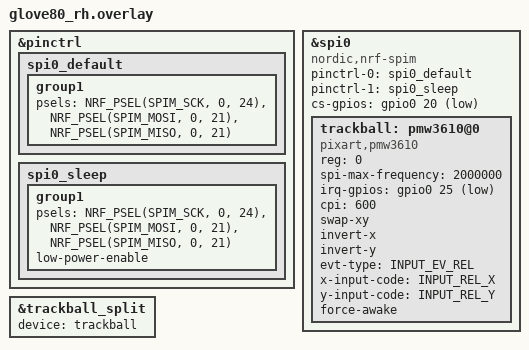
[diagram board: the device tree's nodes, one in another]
/*
 * Copyright (c) 2020 The ZMK Contributors
 *
 * SPDX-License-Identifier: MIT
 */

#include <zephyr/dt-bindings/input/input-event-codes.h>
#include "glove80.dtsi"

/* configure IO pins for the SPI */
&pinctrl {
    spi0_default: spi0_default {
        group1 {
            psels = <NRF_PSEL(SPIM_SCK, 0, 24)>,  // Adjust SCK pin
                    <NRF_PSEL(SPIM_MOSI, 0, 21)>, // Adjust MOSI pin
                    <NRF_PSEL(SPIM_MISO, 0, 21)>; // Adjust MISO pin
        };
    };

    spi0_sleep: spi0_sleep {
        group1 {
            psels = <NRF_PSEL(SPIM_SCK, 0, 24)>,
                    <NRF_PSEL(SPIM_MOSI, 0, 21)>,
                    <NRF_PSEL(SPIM_MISO, 0, 21)>;
            low-power-enable;
        };
    };
};


/* define and configure the trackball connected to SPI channel */
&spi0 {
    status = "okay";
    compatible = "nordic,nrf-spim";
    pinctrl-0 = <&spi0_default>;
    pinctrl-1 = <&spi0_sleep>;
    pinctrl-names = "default", "sleep";
    cs-gpios = <&gpio0 20 GPIO_ACTIVE_LOW>;  // Adjust CS pin

    trackball: pmw3610@0 {
        compatible = "pixart,pmw3610";
        reg = <0>;
        spi-max-frequency = <2000000>;
        irq-gpios = <&gpio0 25 (GPIO_ACTIVE_LOW | GPIO_PULL_UP)>;  // Adjust IRQ/Motion pin
        cpi = <600>;

        /* use the following defines below to properly *
        *  orient your ball direction from the sensor  *
        *  orientation */
        swap-xy; 
        invert-x;
        invert-y;
        /********************************************/
        evt-type = <INPUT_EV_REL>;
        x-input-code = <INPUT_REL_X>;
        y-input-code = <INPUT_REL_Y>;

        force-awake;
        /* keep the sensor awake while ZMK activity state is ACTIVE,
           fallback to normal downshift mode after ZMK goes into IDLE / SLEEP mode.
           thus, the sensor would be a `wakeup-source` */

        //force-awake-4ms-mode;
        /* while force-awake is acitvated, enable this mode to force sampling per 
           4ms, where the default sampling rate is 8ms. */
        /* NOTE: apply this mode if you need 250Hz with direct USB connection. */

    };
};

/* trackball peripheral listener */
&trackball_split {
    device = <&trackball>;
};
